AUTOSAR XML (schema 4-0-3)
package /ComponentTypes
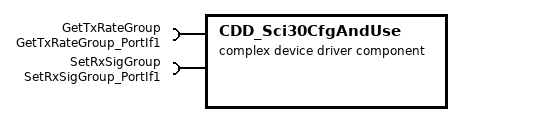
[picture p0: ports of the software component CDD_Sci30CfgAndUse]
  complex device driver sw component type CDD_Sci30CfgAndUse
    require port GetTxRateGroup: required-interface=GetTxRateGroup_PortIf1
    require port SetRxSigGroup: required-interface=SetRxSigGroup_PortIf1
    behavior CDD_Sci30CfgAndUse_InternalBehavior
      exclusive area ExclsvAr1SciDrvrTxRxBuf
      ar-typed-per-instance-memorys:
        13 x data, all with sw-calibration-access=READ-ONLY:
          Sci100MilliSecBufCnt: type=Ary2D_u8_Sci30CfgAndUseC
          Sci100MilliSecReadCmpl: type=boolean
          Sci10MilliSecBufCnt: type=Ary2D_u8_Sci30CfgAndUseB
          Sci10MilliSecReadCmpl: type=boolean
          Sci2MilliSecBufCnt: type=Ary2D_u8_Sci30CfgAndUseA
          SciDiagcFrmErrCntr: type=uint32
          SciDiagcOvrrunErrCntr: type=uint32
          SciDiagcParErrCntr: type=uint32
          SciDiagcRxMaxDataErrCntr: type=uint32
          SciNrOfPnd100MilliSecFrmCnt: type=uint8
          SciNrOfPnd10MilliSecFrmCnt: type=uint8
          SciRxPrevLoopDataUnread: type=uint8
          SciRxProcIdx: type=uint8
      5 x timing event:
        CDD_Sci30CfgAnduse_InitEvent: start-on-event=Sci30CfgAndUseInit1, period=0
        TMT_Sci30CfgAndUsePer5: start-on-event=Sci30CfgAndUsePer1, period=0.002
        TMT_Sci30CfgAndUsePer2: start-on-event=Sci30CfgAndUsePer2, period=0.002
        TMT_Sci30CfgAndUsePer3: start-on-event=Sci30CfgAndUsePer3, period=0.01
        TMT_Sci30CfgAndUsePer4: start-on-event=Sci30CfgAndUsePer4, period=0.1
      5 x runnable:
        Sci30CfgAndUseInit1
        Sci30CfgAndUsePer1: can-enter-exclusive-area=ExclsvAr1SciDrvrTxRxBuf
          sync call SC_SetRxSigGroup_Oper: operation=SetRxSigGroup.Oper, timeout=0
        Sci30CfgAndUsePer2: can-enter-exclusive-area=ExclsvAr1SciDrvrTxRxBuf
          sync call SC_GetTxRateGroup_Oper: operation=GetTxRateGroup.Oper, timeout=0
        Sci30CfgAndUsePer3: can-enter-exclusive-area=ExclsvAr1SciDrvrTxRxBuf
          sync call SC_GetTxRateGroup_Oper: operation=GetTxRateGroup.Oper, timeout=0
        Sci30CfgAndUsePer4: can-enter-exclusive-area=ExclsvAr1SciDrvrTxRxBuf
          sync call SC_GetTxRateGroup_Oper: operation=GetTxRateGroup.Oper, timeout=0
  swc implementation CDD_Sci30CfgAndUse_Implementation: behavior=CDD_Sci30CfgAndUse_InternalBehavior
    code-descriptors:
      code Default: artifact-descriptors=autosar-engineering-object={short-label=Default, category=SWSRC}
